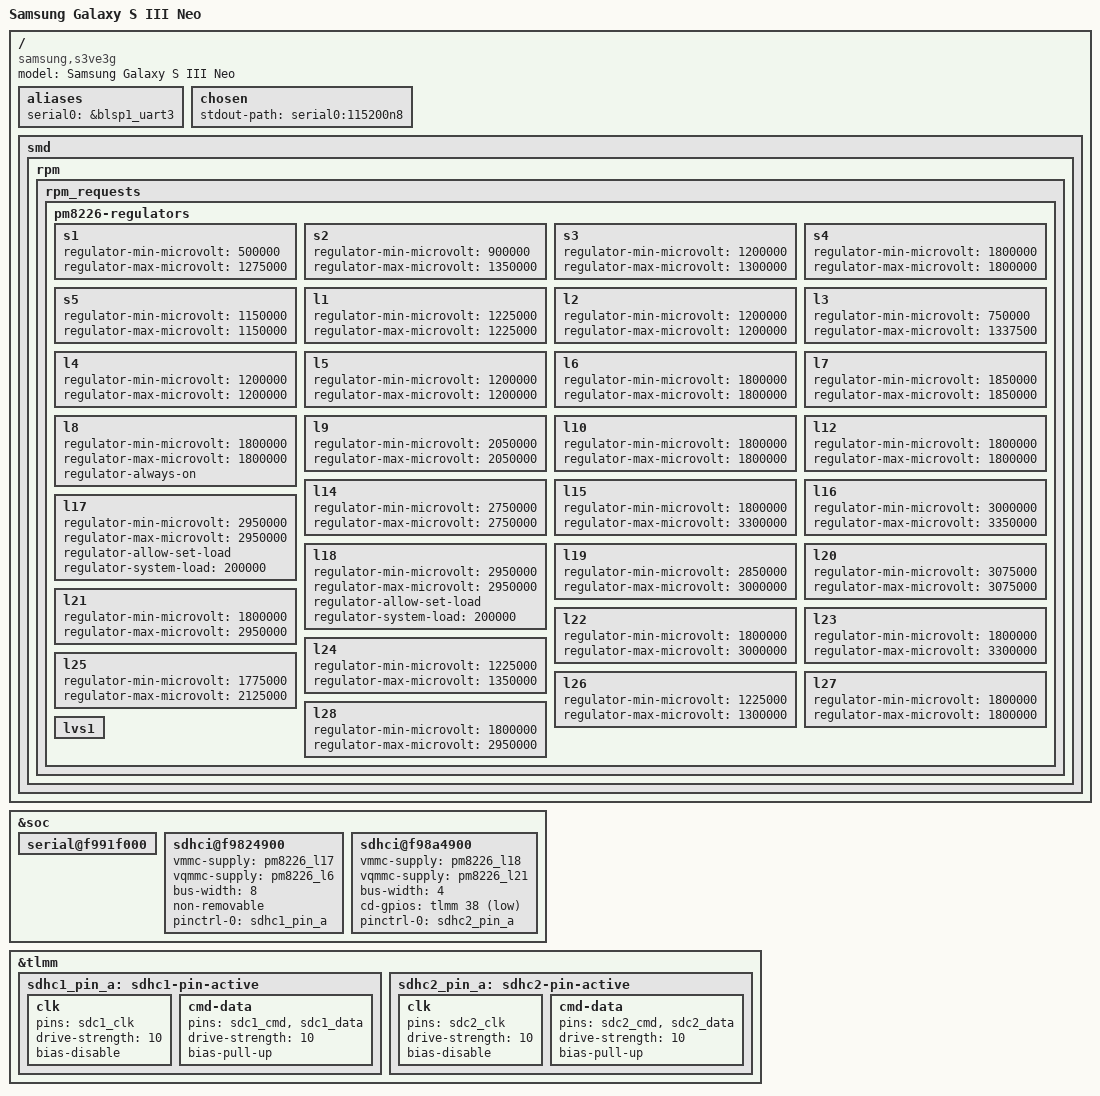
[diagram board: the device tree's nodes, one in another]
// SPDX-License-Identifier: BSD-3-Clause
/*
 * Copyright (c) 2020, The Linux Foundation. All rights reserved.
 */

#include "qcom-msm8226.dtsi"

/ {
	model = "Samsung Galaxy S III Neo";
	compatible = "samsung,s3ve3g", "qcom,msm8226";

	aliases {
		serial0 = &blsp1_uart3;
	};

	chosen {
		stdout-path = "serial0:115200n8";
	};

	smd {
		rpm {
			rpm_requests {
				pm8226-regulators {
					s1 {
						regulator-min-microvolt = <500000>;
						regulator-max-microvolt = <1275000>;
					};

					s2 {
						regulator-min-microvolt = <900000>;
						regulator-max-microvolt = <1350000>;
					};

					s3 {
						regulator-min-microvolt = <1200000>;
						regulator-max-microvolt = <1300000>;
					};

					s4 {
						regulator-min-microvolt = <1800000>;
						regulator-max-microvolt = <1800000>;
					};

					s5 {
						regulator-min-microvolt = <1150000>;
						regulator-max-microvolt = <1150000>;
					};

					l1 {
						regulator-min-microvolt = <1225000>;
						regulator-max-microvolt = <1225000>;
					};

					l2 {
						regulator-min-microvolt = <1200000>;
						regulator-max-microvolt = <1200000>;
					};

					l3 {
						regulator-min-microvolt = <750000>;
						regulator-max-microvolt = <1337500>;
					};

					l4 {
						regulator-min-microvolt = <1200000>;
						regulator-max-microvolt = <1200000>;
					};

					l5 {
						regulator-min-microvolt = <1200000>;
						regulator-max-microvolt = <1200000>;
					};

					l6 {
						regulator-min-microvolt = <1800000>;
						regulator-max-microvolt = <1800000>;
					};

					l7 {
						regulator-min-microvolt = <1850000>;
						regulator-max-microvolt = <1850000>;
					};

					l8 {
						regulator-min-microvolt = <1800000>;
						regulator-max-microvolt = <1800000>;

						regulator-always-on;
					};

					l9 {
						regulator-min-microvolt = <2050000>;
						regulator-max-microvolt = <2050000>;
					};

					l10 {
						regulator-min-microvolt = <1800000>;
						regulator-max-microvolt = <1800000>;
					};

					l12 {
						regulator-min-microvolt = <1800000>;
						regulator-max-microvolt = <1800000>;
					};

					l14 {
						regulator-min-microvolt = <2750000>;
						regulator-max-microvolt = <2750000>;
					};

					l15 {
						regulator-min-microvolt = <1800000>;
						regulator-max-microvolt = <3300000>;
					};

					l16 {
						regulator-min-microvolt = <3000000>;
						regulator-max-microvolt = <3350000>;
					};

					l17 {
						regulator-min-microvolt = <2950000>;
						regulator-max-microvolt = <2950000>;

						regulator-allow-set-load;
						regulator-system-load = <200000>;
					};

					l18 {
						regulator-min-microvolt = <2950000>;
						regulator-max-microvolt = <2950000>;

						regulator-allow-set-load;
						regulator-system-load = <200000>;
					};

					l19 {
						regulator-min-microvolt = <2850000>;
						regulator-max-microvolt = <3000000>;
					};

					l20 {
						regulator-min-microvolt = <3075000>;
						regulator-max-microvolt = <3075000>;
					};

					l21 {
						regulator-min-microvolt = <1800000>;
						regulator-max-microvolt = <2950000>;
					};

					l22 {
						regulator-min-microvolt = <1800000>;
						regulator-max-microvolt = <3000000>;
					};

					l23 {
						regulator-min-microvolt = <1800000>;
						regulator-max-microvolt = <3300000>;
					};

					l24 {
						regulator-min-microvolt = <1225000>;
						regulator-max-microvolt = <1350000>;
					};

					l25 {
						regulator-min-microvolt = <1775000>;
						regulator-max-microvolt = <2125000>;
					};

					l26 {
						regulator-min-microvolt = <1225000>;
						regulator-max-microvolt = <1300000>;
					};

					l27 {
						regulator-min-microvolt = <1800000>;
						regulator-max-microvolt = <1800000>;
					};

					l28 {
						regulator-min-microvolt = <1800000>;
						regulator-max-microvolt = <2950000>;
					};

					lvs1 {};
				};
			};
		};
	};
};

&soc {
	serial@f991f000 {
		status = "ok";
	};

	sdhci@f9824900 {
		status = "ok";

		vmmc-supply = <&pm8226_l17>;
		vqmmc-supply = <&pm8226_l6>;

		bus-width = <8>;
		non-removable;

		pinctrl-names = "default";
		pinctrl-0 = <&sdhc1_pin_a>;
	};

	sdhci@f98a4900 {
		status = "ok";

		vmmc-supply = <&pm8226_l18>;
		vqmmc-supply = <&pm8226_l21>;

		bus-width = <4>;
		cd-gpios = <&tlmm 38 GPIO_ACTIVE_LOW>;

		pinctrl-names = "default";
		pinctrl-0 = <&sdhc2_pin_a>;
	};
};

&tlmm {
	sdhc1_pin_a: sdhc1-pin-active {
		clk {
			pins = "sdc1_clk";
			drive-strength = <10>;
			bias-disable;
		};

		cmd-data {
			pins = "sdc1_cmd", "sdc1_data";
			drive-strength = <10>;
			bias-pull-up;
		};
	};

	sdhc2_pin_a: sdhc2-pin-active {
		clk {
			pins = "sdc2_clk";
			drive-strength = <10>;
			bias-disable;
		};

		cmd-data {
			pins = "sdc2_cmd", "sdc2_data";
			drive-strength = <10>;
			bias-pull-up;
		};
	};
};
